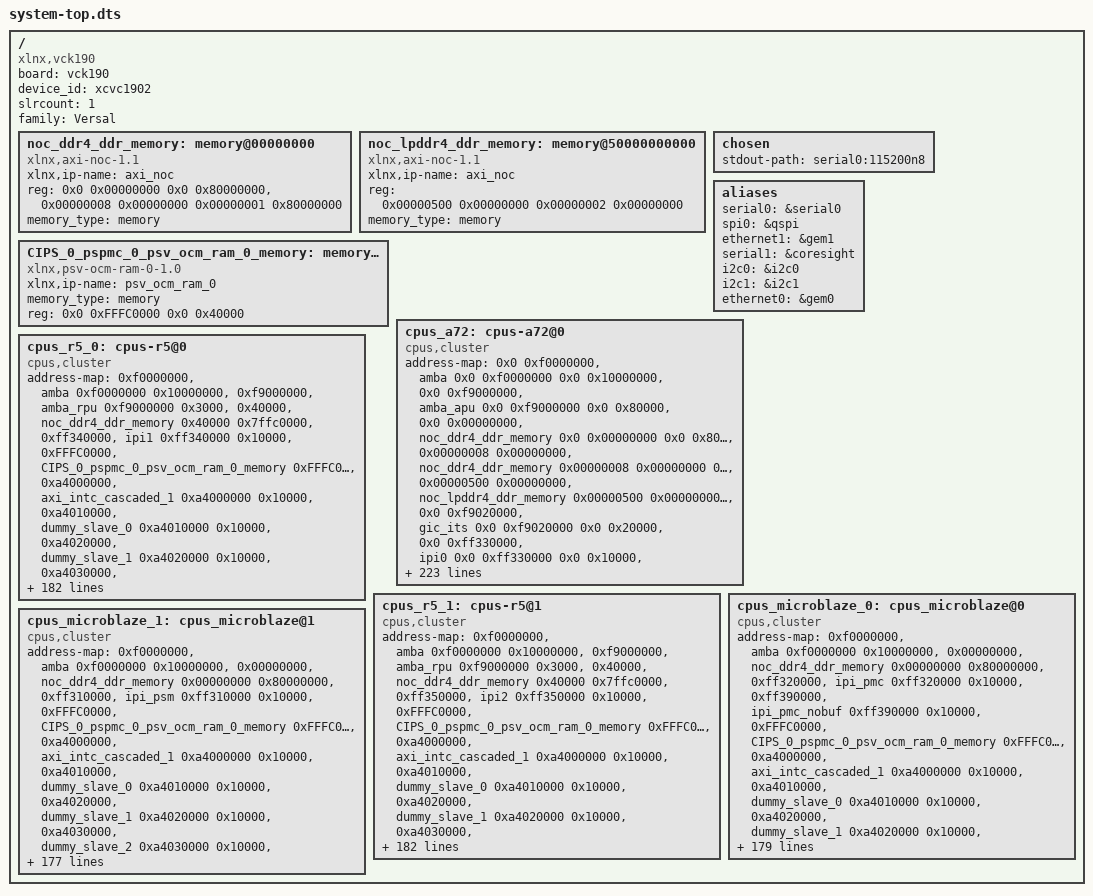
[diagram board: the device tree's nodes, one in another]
/dts-v1/;
#include "versal.dtsi"
#include "versal-clk.dtsi"
#include "pl.dtsi"
#include "pcw.dtsi"
/ {
	board = "vck190";
	compatible = "xlnx,vck190";
	device_id = "xcvc1902";
	slrcount = <1>;
	family = "Versal";
	noc_ddr4_ddr_memory: memory@00000000 {
		compatible = "xlnx,axi-noc-1.1";
		xlnx,ip-name = "axi_noc";
		device_type = "memory";
		reg = <0x0 0x00000000 0x0 0x80000000>, <0x00000008 0x00000000 0x00000001 0x80000000>;
		memory_type = "memory";
	};
	noc_lpddr4_ddr_memory: memory@50000000000 {
		compatible = "xlnx,axi-noc-1.1";
		xlnx,ip-name = "axi_noc";
		device_type = "memory";
		reg = <0x00000500 0x00000000 0x00000002 0x00000000>;
		memory_type = "memory";
	};
	CIPS_0_pspmc_0_psv_ocm_ram_0_memory: memory@FFFC0000 {
		compatible = "xlnx,psv-ocm-ram-0-1.0" , "mmio-sram";
		xlnx,ip-name = "psv_ocm_ram_0";
		device_type = "memory";
		memory_type = "memory";
		reg = <0x0 0xFFFC0000 0x0 0x40000>;
	};
	chosen {
		stdout-path = "serial0:115200n8";
	};
	aliases {
		serial0 = &serial0;
		spi0 = &qspi;
		ethernet1 = &gem1;
		serial1 = &coresight;
		i2c0 = &i2c0;
		i2c1 = &i2c1;
		ethernet0 = &gem0;
	};
	cpus_a72: cpus-a72@0 {
		compatible = "cpus,cluster";
		address-map = <0x0 0xf0000000 &amba 0x0 0xf0000000 0x0 0x10000000>, 
			      <0x0 0xf9000000 &amba_apu 0x0 0xf9000000 0x0 0x80000>, 
			      <0x0 0x00000000 &noc_ddr4_ddr_memory 0x0 0x00000000 0x0 0x80000000>, 
			      <0x00000008 0x00000000 &noc_ddr4_ddr_memory 0x00000008 0x00000000 0x00000001 0x80000000>, 
			      <0x00000500 0x00000000 &noc_lpddr4_ddr_memory 0x00000500 0x00000000 0x00000002 0x00000000>, 
			      <0x0 0xf9020000 &gic_its 0x0 0xf9020000 0x0 0x20000>, 
			      <0x0 0xff330000 &ipi0 0x0 0xff330000 0x0 0x10000>, 
			      <0x0 0xff360000 &ipi3 0x0 0xff360000 0x0 0x10000>, 
			      <0x0 0xff370000 &ipi4 0x0 0xff370000 0x0 0x10000>, 
			      <0x0 0xff380000 &ipi5 0x0 0xff380000 0x0 0x10000>, 
			      <0x0 0xff3a0000 &ipi6 0x0 0xff3a0000 0x0 0x10000>, 
			      <0x0 0xFFFC0000 &CIPS_0_pspmc_0_psv_ocm_ram_0_memory 0x0 0xFFFC0000 0x0 0x40000>, 
			      <0x0 0xa4000000 &axi_intc_cascaded_1 0x0 0xa4000000 0x0 0x10000>, 
			      <0x0 0xa4010000 &dummy_slave_0 0x0 0xa4010000 0x0 0x10000>, 
			      <0x0 0xa4020000 &dummy_slave_1 0x0 0xa4020000 0x0 0x10000>, 
			      <0x0 0xa4030000 &dummy_slave_2 0x0 0xa4030000 0x0 0x10000>, 
			      <0x0 0xa4040000 &dummy_slave_3 0x0 0xa4040000 0x0 0x10000>, 
			      <0x0 0xa5000000 &axi_intc_parent 0x0 0xa5000000 0x0 0x10000>, 
			      <0x0 0xf0310000 &CIPS_0_pspmc_0_psv_pmc_ppu1_mdm_0 0x0 0xf0310000 0x0 0x8000>, 
			      <0x0 0xf0800000 &coresight 0x0 0xf0800000 0x0 0x10000>, 
			      <0x0 0xf0980000 &CIPS_0_pspmc_0_psv_coresight_lpd_atm 0x0 0xf0980000 0x0 0x10000>, 
			      <0x0 0xf0b70000 &CIPS_0_pspmc_0_psv_coresight_fpd_stm 0x0 0xf0b70000 0x0 0x10000>, 
			      <0x0 0xf0b80000 &CIPS_0_pspmc_0_psv_coresight_fpd_atm 0x0 0xf0b80000 0x0 0x10000>, 
			      <0x0 0xf0c20000 &CIPS_0_pspmc_0_psv_coresight_apu_fun 0x0 0xf0c20000 0x0 0x10000>, 
			      <0x0 0xf0c30000 &CIPS_0_pspmc_0_psv_coresight_apu_etf 0x0 0xf0c30000 0x0 0x10000>, 
			      <0x0 0xf0c60000 &CIPS_0_pspmc_0_psv_coresight_apu_ela 0x0 0xf0c60000 0x0 0x10000>, 
			      <0x0 0xf0ca0000 &CIPS_0_pspmc_0_psv_coresight_apu_cti 0x0 0xf0ca0000 0x0 0x10000>, 
			      <0x0 0xf0d00000 &CIPS_0_pspmc_0_psv_coresight_a720_dbg 0x0 0xf0d00000 0x0 0x10000>, 
			      <0x0 0xf0d10000 &CIPS_0_pspmc_0_psv_coresight_a720_cti 0x0 0xf0d10000 0x0 0x10000>, 
			      <0x0 0xf0d20000 &CIPS_0_pspmc_0_psv_coresight_a720_pmu 0x0 0xf0d20000 0x0 0x10000>, 
			      <0x0 0xf0d30000 &CIPS_0_pspmc_0_psv_coresight_a720_etm 0x0 0xf0d30000 0x0 0x10000>, 
			      <0x0 0xf0d40000 &CIPS_0_pspmc_0_psv_coresight_a721_dbg 0x0 0xf0d40000 0x0 0x10000>, 
			      <0x0 0xf0d50000 &CIPS_0_pspmc_0_psv_coresight_a721_cti 0x0 0xf0d50000 0x0 0x10000>, 
			      <0x0 0xf0d60000 &CIPS_0_pspmc_0_psv_coresight_a721_pmu 0x0 0xf0d60000 0x0 0x10000>, 
			      <0x0 0xf0d70000 &CIPS_0_pspmc_0_psv_coresight_a721_etm 0x0 0xf0d70000 0x0 0x10000>, 
			      <0x0 0xf0f00000 &CIPS_0_pspmc_0_psv_coresight_cpm_rom 0x0 0xf0f00000 0x0 0x10000>, 
			      <0x0 0xf0f20000 &CIPS_0_pspmc_0_psv_coresight_cpm_fun 0x0 0xf0f20000 0x0 0x10000>, 
			      <0x0 0xf0f40000 &CIPS_0_pspmc_0_psv_coresight_cpm_ela2a 0x0 0xf0f40000 0x0 0x10000>, 
			      <0x0 0xf0f50000 &CIPS_0_pspmc_0_psv_coresight_cpm_ela2b 0x0 0xf0f50000 0x0 0x10000>, 
			      <0x0 0xf0f60000 &CIPS_0_pspmc_0_psv_coresight_cpm_ela2c 0x0 0xf0f60000 0x0 0x10000>, 
			      <0x0 0xf0f70000 &CIPS_0_pspmc_0_psv_coresight_cpm_ela2d 0x0 0xf0f70000 0x0 0x10000>, 
			      <0x0 0xf0f80000 &CIPS_0_pspmc_0_psv_coresight_cpm_atm 0x0 0xf0f80000 0x0 0x10000>, 
			      <0x0 0xf0fa0000 &CIPS_0_pspmc_0_psv_coresight_cpm_cti2a 0x0 0xf0fa0000 0x0 0x10000>, 
			      <0x0 0xf0fd0000 &CIPS_0_pspmc_0_psv_coresight_cpm_cti2d 0x0 0xf0fd0000 0x0 0x10000>, 
			      <0x0 0xf1020000 &gpio1 0x0 0xf1020000 0x0 0x10000>, 
			      <0x0 0xf1030000 &qspi 0x0 0xf1030000 0x0 0x10000>, 
			      <0x0 0xf1050000 &sdhci1 0x0 0xf1050000 0x0 0x10000>, 
			      <0x0 0xf1110000 &CIPS_0_pspmc_0_psv_pmc_global_0 0x0 0xf1110000 0x0 0x50000>, 
			      <0x0 0xf11c0000 &dma0 0x0 0xf11c0000 0x0 0x10000>, 
			      <0x0 0xf11d0000 &dma1 0x0 0xf11d0000 0x0 0x10000>, 
			      <0x0 0xf11e0000 &CIPS_0_pspmc_0_psv_pmc_aes 0x0 0xf11e0000 0x0 0x10000>, 
			      <0x0 0xf11f0000 &CIPS_0_pspmc_0_psv_pmc_bbram_ctrl 0x0 0xf11f0000 0x0 0x10000>, 
			      <0x0 0xf1200000 &CIPS_0_pspmc_0_psv_pmc_rsa 0x0 0xf1200000 0x0 0x10000>, 
			      <0x0 0xf1210000 &CIPS_0_pspmc_0_psv_pmc_sha 0x0 0xf1210000 0x0 0x10000>, 
			      <0x0 0xf1220000 &CIPS_0_pspmc_0_psv_pmc_slave_boot 0x0 0xf1220000 0x0 0x10000>, 
			      <0x0 0xf1230000 &CIPS_0_pspmc_0_psv_pmc_trng 0x0 0xf1230000 0x0 0x10000>, 
			      <0x0 0xf1240000 &CIPS_0_pspmc_0_psv_pmc_efuse_ctrl 0x0 0xf1240000 0x0 0x10000>, 
			      <0x0 0xf1250000 &CIPS_0_pspmc_0_psv_pmc_efuse_cache 0x0 0xf1250000 0x0 0x10000>, 
			      <0x0 0xf1260000 &CIPS_0_pspmc_0_psv_crp_0 0x0 0xf1260000 0x0 0x10000>, 
			      <0x0 0xf1270000 &sysmon0 0x0 0xf1270000 0x0 0x30000>, 
			      <0x0 0xf12a0000 &rtc 0x0 0xf12a0000 0x0 0x10000>, 
			      <0x0 0xf12b0000 &CIPS_0_pspmc_0_psv_pmc_cfu_apb_0 0x0 0xf12b0000 0x0 0x10000>, 
			      <0x0 0xf12d0000 &CIPS_0_pspmc_0_psv_pmc_cfi_cframe_0 0x0 0xf12d0000 0x0 0x1000>, 
			      <0x0 0xf12f0000 &pmc_xmpu 0x0 0xf12f0000 0x0 0x10000>, 
			      <0x0 0xf1300000 &pmc_xppu_npi 0x0 0xf1300000 0x0 0x10000>, 
			      <0x0 0xf1310000 &pmc_xppu 0x0 0xf1310000 0x0 0x10000>, 
			      <0x0 0xf2100000 &CIPS_0_pspmc_0_psv_pmc_slave_boot_stream 0x0 0xf2100000 0x0 0x10000>, 
			      <0x0 0xf6000000 &CIPS_0_pspmc_0_psv_pmc_ram_npi 0x0 0xf6000000 0x0 0x2000000>, 
			      <0x0 0xf9000000 &gic_a72 0x0 0xf9000000 0x0 0x70000>, 
			      <0x0 0 &CIPS_0_pspmc_0_psv_cpm 0x0 0 0x0 0xfd000000>, 
			      <0x0 0xfd000000 &cci 0x0 0xfd000000 0x0 0x100000>, 
			      <0x0 0xfd1a0000 &CIPS_0_pspmc_0_psv_crf_0 0x0 0xfd1a0000 0x0 0x140000>, 
			      <0x0 0xfd360000 &CIPS_0_pspmc_0_psv_fpd_afi_0 0x0 0xfd360000 0x0 0x10000>, 
			      <0x0 0xfd380000 &CIPS_0_pspmc_0_psv_fpd_afi_2 0x0 0xfd380000 0x0 0x10000>, 
			      <0x0 0xfd390000 &fpd_xmpu 0x0 0xfd390000 0x0 0x10000>, 
			      <0x0 0xfd5c0000 &CIPS_0_pspmc_0_psv_apu_0 0x0 0xfd5c0000 0x0 0x10000>, 
			      <0x0 0xfd5e0000 &CIPS_0_pspmc_0_psv_fpd_cci_0 0x0 0xfd5e0000 0x0 0x10000>, 
			      <0x0 0xfd5f0000 &CIPS_0_pspmc_0_psv_fpd_smmu_0 0x0 0xfd5f0000 0x0 0x10000>, 
			      <0x0 0xfd610000 &CIPS_0_pspmc_0_psv_fpd_slcr_0 0x0 0xfd610000 0x0 0x10000>, 
			      <0x0 0xfd690000 &CIPS_0_pspmc_0_psv_fpd_slcr_secure_0 0x0 0xfd690000 0x0 0x10000>, 
			      <0x0 0xfd700000 &CIPS_0_pspmc_0_psv_fpd_gpv_0 0x0 0xfd700000 0x0 0x100000>, 
			      <0x0 0xfd800000 &smmu 0x0 0xfd800000 0x0 0x800000>, 
			      <0x0 0xfe200000 &dwc3_0 0x0 0xfe200000 0x0 0x100000>, 
			      <0x0 0xff000000 &serial0 0x0 0xff000000 0x0 0x10000>, 
			      <0x0 0xff020000 &i2c0 0x0 0xff020000 0x0 0x10000>, 
			      <0x0 0xff030000 &i2c1 0x0 0xff030000 0x0 0x10000>, 
			      <0x0 0xff070000 &can1 0x0 0xff070000 0x0 0x10000>, 
			      <0x0 0xff080000 &CIPS_0_pspmc_0_psv_lpd_iou_slcr_0 0x0 0xff080000 0x0 0x20000>, 
			      <0x0 0xff0a0000 &CIPS_0_pspmc_0_psv_lpd_iou_secure_slcr_0 0x0 0xff0a0000 0x0 0x10000>, 
			      <0x0 0xff0c0000 &gem0 0x0 0xff0c0000 0x0 0x10000>, 
			      <0x0 0xff0d0000 &gem1 0x0 0xff0d0000 0x0 0x10000>, 
			      <0x0 0xff0e0000 &ttc0 0x0 0xff0e0000 0x0 0x10000>, 
			      <0x0 0xff0f0000 &ttc1 0x0 0xff0f0000 0x0 0x10000>, 
			      <0x0 0xff100000 &ttc2 0x0 0xff100000 0x0 0x10000>, 
			      <0x0 0xff110000 &ttc3 0x0 0xff110000 0x0 0x10000>, 
			      <0x0 0xff130000 &CIPS_0_pspmc_0_psv_scntr_0 0x0 0xff130000 0x0 0x10000>, 
			      <0x0 0xff140000 &CIPS_0_pspmc_0_psv_scntrs_0 0x0 0xff140000 0x0 0x10000>, 
			      <0x0 0xff410000 &CIPS_0_pspmc_0_psv_lpd_slcr_0 0x0 0xff410000 0x0 0x100000>, 
			      <0x0 0xff510000 &CIPS_0_pspmc_0_psv_lpd_slcr_secure_0 0x0 0xff510000 0x0 0x40000>, 
			      <0x0 0xff5e0000 &CIPS_0_pspmc_0_psv_crl_0 0x0 0xff5e0000 0x0 0x300000>, 
			      <0x0 0xff960000 &CIPS_0_pspmc_0_psv_ocm_ctrl 0x0 0xff960000 0x0 0x10000>, 
			      <0x0 0xff980000 &ocm_xmpu 0x0 0xff980000 0x0 0x10000>, 
			      <0x0 0xff990000 &lpd_xppu 0x0 0xff990000 0x0 0x10000>, 
			      <0x0 0xff9a0000 &CIPS_0_pspmc_0_psv_rpu_0 0x0 0xff9a0000 0x0 0x10000>, 
			      <0x0 0xff9b0000 &CIPS_0_pspmc_0_psv_lpd_afi_0 0x0 0xff9b0000 0x0 0x10000>, 
			      <0x0 0xff9d0000 &usb0 0x0 0xff9d0000 0x0 0x10000>, 
			      <0x0 0xffa80000 &lpd_dma_chan0 0x0 0xffa80000 0x0 0x10000>, 
			      <0x0 0xffa90000 &lpd_dma_chan1 0x0 0xffa90000 0x0 0x10000>, 
			      <0x0 0xffaa0000 &lpd_dma_chan2 0x0 0xffaa0000 0x0 0x10000>, 
			      <0x0 0xffab0000 &lpd_dma_chan3 0x0 0xffab0000 0x0 0x10000>, 
			      <0x0 0xffac0000 &lpd_dma_chan4 0x0 0xffac0000 0x0 0x10000>, 
			      <0x0 0xffad0000 &lpd_dma_chan5 0x0 0xffad0000 0x0 0x10000>, 
			      <0x0 0xffae0000 &lpd_dma_chan6 0x0 0xffae0000 0x0 0x10000>, 
			      <0x0 0xffaf0000 &lpd_dma_chan7 0x0 0xffaf0000 0x0 0x10000>, 
			      <0x0 0xffc90000 &CIPS_0_pspmc_0_psv_psm_global_reg 0x0 0xffc90000 0x0 0xf000>, 
			      <0x0 0xffe00000 &psv_r5_0_atcm_global 0x0 0xffe00000 0x0 0x40000>, 
			      <0x0 0xffe90000 &psv_r5_1_atcm_global 0x0 0xffe90000 0x0 0x10000>, 
			      <0x0 0xffeb0000 &psv_r5_1_btcm_global 0x0 0xffeb0000 0x0 0x10000>, 
			      <0x00000200 0x00000000 &ai_engine_0 0x00000200 0x00000000 0x00000001 0x00000000>;
		#ranges-address-cells = <0x2>;
		#ranges-size-cells = <0x2>;
	};
	cpus_r5_0: cpus-r5@0 {
		compatible = "cpus,cluster";
		address-map = <0xf0000000 &amba 0xf0000000 0x10000000>, 
			      <0xf9000000 &amba_rpu 0xf9000000 0x3000>, 
			      <0x40000 &noc_ddr4_ddr_memory 0x40000 0x7ffc0000>, 
			      <0xff340000 &ipi1 0xff340000 0x10000>, 
			      <0xFFFC0000 &CIPS_0_pspmc_0_psv_ocm_ram_0_memory 0xFFFC0000 0x40000>, 
			      <0xa4000000 &axi_intc_cascaded_1 0xa4000000 0x10000>, 
			      <0xa4010000 &dummy_slave_0 0xa4010000 0x10000>, 
			      <0xa4020000 &dummy_slave_1 0xa4020000 0x10000>, 
			      <0xa4030000 &dummy_slave_2 0xa4030000 0x10000>, 
			      <0xa4040000 &dummy_slave_3 0xa4040000 0x10000>, 
			      <0xa5000000 &axi_intc_parent 0xa5000000 0x10000>, 
			      <0xf0310000 &CIPS_0_pspmc_0_psv_pmc_ppu1_mdm_0 0xf0310000 0x8000>, 
			      <0xf0800000 &coresight 0xf0800000 0x10000>, 
			      <0xf0980000 &CIPS_0_pspmc_0_psv_coresight_lpd_atm 0xf0980000 0x10000>, 
			      <0xf0b70000 &CIPS_0_pspmc_0_psv_coresight_fpd_stm 0xf0b70000 0x10000>, 
			      <0xf0b80000 &CIPS_0_pspmc_0_psv_coresight_fpd_atm 0xf0b80000 0x10000>, 
			      <0xf0c20000 &CIPS_0_pspmc_0_psv_coresight_apu_fun 0xf0c20000 0x10000>, 
			      <0xf0c30000 &CIPS_0_pspmc_0_psv_coresight_apu_etf 0xf0c30000 0x10000>, 
			      <0xf0c60000 &CIPS_0_pspmc_0_psv_coresight_apu_ela 0xf0c60000 0x10000>, 
			      <0xf0ca0000 &CIPS_0_pspmc_0_psv_coresight_apu_cti 0xf0ca0000 0x10000>, 
			      <0xf0d00000 &CIPS_0_pspmc_0_psv_coresight_a720_dbg 0xf0d00000 0x10000>, 
			      <0xf0d10000 &CIPS_0_pspmc_0_psv_coresight_a720_cti 0xf0d10000 0x10000>, 
			      <0xf0d20000 &CIPS_0_pspmc_0_psv_coresight_a720_pmu 0xf0d20000 0x10000>, 
			      <0xf0d30000 &CIPS_0_pspmc_0_psv_coresight_a720_etm 0xf0d30000 0x10000>, 
			      <0xf0d40000 &CIPS_0_pspmc_0_psv_coresight_a721_dbg 0xf0d40000 0x10000>, 
			      <0xf0d50000 &CIPS_0_pspmc_0_psv_coresight_a721_cti 0xf0d50000 0x10000>, 
			      <0xf0d60000 &CIPS_0_pspmc_0_psv_coresight_a721_pmu 0xf0d60000 0x10000>, 
			      <0xf0d70000 &CIPS_0_pspmc_0_psv_coresight_a721_etm 0xf0d70000 0x10000>, 
			      <0xf0f00000 &CIPS_0_pspmc_0_psv_coresight_cpm_rom 0xf0f00000 0x10000>, 
			      <0xf0f20000 &CIPS_0_pspmc_0_psv_coresight_cpm_fun 0xf0f20000 0x10000>, 
			      <0xf0f40000 &CIPS_0_pspmc_0_psv_coresight_cpm_ela2a 0xf0f40000 0x10000>, 
			      <0xf0f50000 &CIPS_0_pspmc_0_psv_coresight_cpm_ela2b 0xf0f50000 0x10000>, 
			      <0xf0f60000 &CIPS_0_pspmc_0_psv_coresight_cpm_ela2c 0xf0f60000 0x10000>, 
			      <0xf0f70000 &CIPS_0_pspmc_0_psv_coresight_cpm_ela2d 0xf0f70000 0x10000>, 
			      <0xf0f80000 &CIPS_0_pspmc_0_psv_coresight_cpm_atm 0xf0f80000 0x10000>, 
			      <0xf0fa0000 &CIPS_0_pspmc_0_psv_coresight_cpm_cti2a 0xf0fa0000 0x10000>, 
			      <0xf0fd0000 &CIPS_0_pspmc_0_psv_coresight_cpm_cti2d 0xf0fd0000 0x10000>, 
			      <0xf1020000 &gpio1 0xf1020000 0x10000>, 
			      <0xf1030000 &qspi 0xf1030000 0x10000>, 
			      <0xf1050000 &sdhci1 0xf1050000 0x10000>, 
			      <0xf1110000 &CIPS_0_pspmc_0_psv_pmc_global_0 0xf1110000 0x50000>, 
			      <0xf11c0000 &dma0 0xf11c0000 0x10000>, 
			      <0xf11d0000 &dma1 0xf11d0000 0x10000>, 
			      <0xf11e0000 &CIPS_0_pspmc_0_psv_pmc_aes 0xf11e0000 0x10000>, 
			      <0xf11f0000 &CIPS_0_pspmc_0_psv_pmc_bbram_ctrl 0xf11f0000 0x10000>, 
			      <0xf1200000 &CIPS_0_pspmc_0_psv_pmc_rsa 0xf1200000 0x10000>, 
			      <0xf1210000 &CIPS_0_pspmc_0_psv_pmc_sha 0xf1210000 0x10000>, 
			      <0xf1220000 &CIPS_0_pspmc_0_psv_pmc_slave_boot 0xf1220000 0x10000>, 
			      <0xf1230000 &CIPS_0_pspmc_0_psv_pmc_trng 0xf1230000 0x10000>, 
			      <0xf1240000 &CIPS_0_pspmc_0_psv_pmc_efuse_ctrl 0xf1240000 0x10000>, 
			      <0xf1250000 &CIPS_0_pspmc_0_psv_pmc_efuse_cache 0xf1250000 0x10000>, 
			      <0xf1260000 &CIPS_0_pspmc_0_psv_crp_0 0xf1260000 0x10000>, 
			      <0xf1270000 &sysmon0 0xf1270000 0x30000>, 
			      <0xf12a0000 &rtc 0xf12a0000 0x10000>, 
			      <0xf12b0000 &CIPS_0_pspmc_0_psv_pmc_cfu_apb_0 0xf12b0000 0x10000>, 
			      <0xf12d0000 &CIPS_0_pspmc_0_psv_pmc_cfi_cframe_0 0xf12d0000 0x1000>, 
			      <0xf12f0000 &pmc_xmpu 0xf12f0000 0x10000>, 
			      <0xf1300000 &pmc_xppu_npi 0xf1300000 0x10000>, 
			      <0xf1310000 &pmc_xppu 0xf1310000 0x10000>, 
			      <0xf2100000 &CIPS_0_pspmc_0_psv_pmc_slave_boot_stream 0xf2100000 0x10000>, 
			      <0xf6000000 &CIPS_0_pspmc_0_psv_pmc_ram_npi 0xf6000000 0x2000000>, 
			      <0xfd000000 &cci 0xfd000000 0x100000>, 
			      <0xfd1a0000 &CIPS_0_pspmc_0_psv_crf_0 0xfd1a0000 0x140000>, 
			      <0xfd360000 &CIPS_0_pspmc_0_psv_fpd_afi_0 0xfd360000 0x10000>, 
			      <0xfd380000 &CIPS_0_pspmc_0_psv_fpd_afi_2 0xfd380000 0x10000>, 
			      <0xfd390000 &fpd_xmpu 0xfd390000 0x10000>, 
			      <0xfd5c0000 &CIPS_0_pspmc_0_psv_apu_0 0xfd5c0000 0x10000>, 
			      <0xfd5e0000 &CIPS_0_pspmc_0_psv_fpd_cci_0 0xfd5e0000 0x10000>, 
			      <0xfd5f0000 &CIPS_0_pspmc_0_psv_fpd_smmu_0 0xfd5f0000 0x10000>, 
			      <0xfd610000 &CIPS_0_pspmc_0_psv_fpd_slcr_0 0xfd610000 0x10000>, 
			      <0xfd690000 &CIPS_0_pspmc_0_psv_fpd_slcr_secure_0 0xfd690000 0x10000>, 
			      <0xfd700000 &CIPS_0_pspmc_0_psv_fpd_gpv_0 0xfd700000 0x100000>, 
			      <0xfd800000 &smmu 0xfd800000 0x800000>, 
			      <0xfe200000 &dwc3_0 0xfe200000 0x100000>, 
			      <0xff000000 &serial0 0xff000000 0x10000>, 
			      <0xff020000 &i2c0 0xff020000 0x10000>, 
			      <0xff030000 &i2c1 0xff030000 0x10000>, 
			      <0xff070000 &can1 0xff070000 0x10000>, 
			      <0xff080000 &CIPS_0_pspmc_0_psv_lpd_iou_slcr_0 0xff080000 0x20000>, 
			      <0xff0a0000 &CIPS_0_pspmc_0_psv_lpd_iou_secure_slcr_0 0xff0a0000 0x10000>, 
			      <0xff0c0000 &gem0 0xff0c0000 0x10000>, 
			      <0xff0d0000 &gem1 0xff0d0000 0x10000>, 
			      <0xff0e0000 &ttc0 0xff0e0000 0x10000>, 
			      <0xff0f0000 &ttc1 0xff0f0000 0x10000>, 
			      <0xff100000 &ttc2 0xff100000 0x10000>, 
			      <0xff110000 &ttc3 0xff110000 0x10000>, 
			      <0xff130000 &CIPS_0_pspmc_0_psv_scntr_0 0xff130000 0x10000>, 
			      <0xff140000 &CIPS_0_pspmc_0_psv_scntrs_0 0xff140000 0x10000>, 
			      <0xff410000 &CIPS_0_pspmc_0_psv_lpd_slcr_0 0xff410000 0x100000>, 
			      <0xff510000 &CIPS_0_pspmc_0_psv_lpd_slcr_secure_0 0xff510000 0x40000>, 
			      <0xff5e0000 &CIPS_0_pspmc_0_psv_crl_0 0xff5e0000 0x300000>, 
			      <0xff960000 &CIPS_0_pspmc_0_psv_ocm_ctrl 0xff960000 0x10000>, 
			      <0xff980000 &ocm_xmpu 0xff980000 0x10000>, 
			      <0xff990000 &lpd_xppu 0xff990000 0x10000>, 
			      <0xff9a0000 &CIPS_0_pspmc_0_psv_rpu_0 0xff9a0000 0x10000>, 
			      <0xff9b0000 &CIPS_0_pspmc_0_psv_lpd_afi_0 0xff9b0000 0x10000>, 
			      <0xff9d0000 &usb0 0xff9d0000 0x10000>, 
			      <0xffa80000 &lpd_dma_chan0 0xffa80000 0x10000>, 
			      <0xffa90000 &lpd_dma_chan1 0xffa90000 0x10000>, 
			      <0xffaa0000 &lpd_dma_chan2 0xffaa0000 0x10000>, 
			      <0xffab0000 &lpd_dma_chan3 0xffab0000 0x10000>, 
			      <0xffac0000 &lpd_dma_chan4 0xffac0000 0x10000>, 
			      <0xffad0000 &lpd_dma_chan5 0xffad0000 0x10000>, 
			      <0xffae0000 &lpd_dma_chan6 0xffae0000 0x10000>, 
			      <0xffaf0000 &lpd_dma_chan7 0xffaf0000 0x10000>, 
			      <0xffc90000 &CIPS_0_pspmc_0_psv_psm_global_reg 0xffc90000 0xf000>, 
			      <0x0000 &CIPS_0_pspmc_0_psv_r5_0_atcm 0x0000 0x10000>, 
			      <0x00000 &CIPS_0_pspmc_0_psv_r5_tcm_ram_0 0x00000 0x40000>, 
			      <0x20000 &CIPS_0_pspmc_0_psv_r5_0_btcm 0x20000 0x10000>, 
			      <0xf9000000 &gic_r5 0xf9000000 0x3000>, 
			      <0xffe40000 &CIPS_0_pspmc_0_psv_r5_0_instruction_cache 0xffe40000 0x10000>, 
			      <0xffe50000 &CIPS_0_pspmc_0_psv_r5_0_data_cache 0xffe50000 0x10000>, 
			      <0xffec0000 &CIPS_0_pspmc_0_psv_r5_1_instruction_cache 0xffec0000 0x10000>, 
			      <0xffed0000 &CIPS_0_pspmc_0_psv_r5_1_data_cache 0xffed0000 0x10000>;
		#ranges-address-cells = <0x1>;
		#ranges-size-cells = <0x1>;
	};
	cpus_r5_1: cpus-r5@1 {
		compatible = "cpus,cluster";
		address-map = <0xf0000000 &amba 0xf0000000 0x10000000>, 
			      <0xf9000000 &amba_rpu 0xf9000000 0x3000>, 
			      <0x40000 &noc_ddr4_ddr_memory 0x40000 0x7ffc0000>, 
			      <0xff350000 &ipi2 0xff350000 0x10000>, 
			      <0xFFFC0000 &CIPS_0_pspmc_0_psv_ocm_ram_0_memory 0xFFFC0000 0x40000>, 
			      <0xa4000000 &axi_intc_cascaded_1 0xa4000000 0x10000>, 
			      <0xa4010000 &dummy_slave_0 0xa4010000 0x10000>, 
			      <0xa4020000 &dummy_slave_1 0xa4020000 0x10000>, 
			      <0xa4030000 &dummy_slave_2 0xa4030000 0x10000>, 
			      <0xa4040000 &dummy_slave_3 0xa4040000 0x10000>, 
			      <0xa5000000 &axi_intc_parent 0xa5000000 0x10000>, 
			      <0xf0310000 &CIPS_0_pspmc_0_psv_pmc_ppu1_mdm_0 0xf0310000 0x8000>, 
			      <0xf0800000 &coresight 0xf0800000 0x10000>, 
			      <0xf0980000 &CIPS_0_pspmc_0_psv_coresight_lpd_atm 0xf0980000 0x10000>, 
			      <0xf0b70000 &CIPS_0_pspmc_0_psv_coresight_fpd_stm 0xf0b70000 0x10000>, 
			      <0xf0b80000 &CIPS_0_pspmc_0_psv_coresight_fpd_atm 0xf0b80000 0x10000>, 
			      <0xf0c20000 &CIPS_0_pspmc_0_psv_coresight_apu_fun 0xf0c20000 0x10000>, 
			      <0xf0c30000 &CIPS_0_pspmc_0_psv_coresight_apu_etf 0xf0c30000 0x10000>, 
			      <0xf0c60000 &CIPS_0_pspmc_0_psv_coresight_apu_ela 0xf0c60000 0x10000>, 
			      <0xf0ca0000 &CIPS_0_pspmc_0_psv_coresight_apu_cti 0xf0ca0000 0x10000>, 
			      <0xf0d00000 &CIPS_0_pspmc_0_psv_coresight_a720_dbg 0xf0d00000 0x10000>, 
			      <0xf0d10000 &CIPS_0_pspmc_0_psv_coresight_a720_cti 0xf0d10000 0x10000>, 
			      <0xf0d20000 &CIPS_0_pspmc_0_psv_coresight_a720_pmu 0xf0d20000 0x10000>, 
			      <0xf0d30000 &CIPS_0_pspmc_0_psv_coresight_a720_etm 0xf0d30000 0x10000>, 
			      <0xf0d40000 &CIPS_0_pspmc_0_psv_coresight_a721_dbg 0xf0d40000 0x10000>, 
			      <0xf0d50000 &CIPS_0_pspmc_0_psv_coresight_a721_cti 0xf0d50000 0x10000>, 
			      <0xf0d60000 &CIPS_0_pspmc_0_psv_coresight_a721_pmu 0xf0d60000 0x10000>, 
			      <0xf0d70000 &CIPS_0_pspmc_0_psv_coresight_a721_etm 0xf0d70000 0x10000>, 
			      <0xf0f00000 &CIPS_0_pspmc_0_psv_coresight_cpm_rom 0xf0f00000 0x10000>, 
			      <0xf0f20000 &CIPS_0_pspmc_0_psv_coresight_cpm_fun 0xf0f20000 0x10000>, 
			      <0xf0f40000 &CIPS_0_pspmc_0_psv_coresight_cpm_ela2a 0xf0f40000 0x10000>, 
			      <0xf0f50000 &CIPS_0_pspmc_0_psv_coresight_cpm_ela2b 0xf0f50000 0x10000>, 
			      <0xf0f60000 &CIPS_0_pspmc_0_psv_coresight_cpm_ela2c 0xf0f60000 0x10000>, 
			      <0xf0f70000 &CIPS_0_pspmc_0_psv_coresight_cpm_ela2d 0xf0f70000 0x10000>, 
			      <0xf0f80000 &CIPS_0_pspmc_0_psv_coresight_cpm_atm 0xf0f80000 0x10000>, 
			      <0xf0fa0000 &CIPS_0_pspmc_0_psv_coresight_cpm_cti2a 0xf0fa0000 0x10000>, 
			      <0xf0fd0000 &CIPS_0_pspmc_0_psv_coresight_cpm_cti2d 0xf0fd0000 0x10000>, 
			      <0xf1020000 &gpio1 0xf1020000 0x10000>, 
			      <0xf1030000 &qspi 0xf1030000 0x10000>, 
			      <0xf1050000 &sdhci1 0xf1050000 0x10000>, 
			      <0xf1110000 &CIPS_0_pspmc_0_psv_pmc_global_0 0xf1110000 0x50000>, 
			      <0xf11c0000 &dma0 0xf11c0000 0x10000>, 
			      <0xf11d0000 &dma1 0xf11d0000 0x10000>, 
			      <0xf11e0000 &CIPS_0_pspmc_0_psv_pmc_aes 0xf11e0000 0x10000>, 
			      <0xf11f0000 &CIPS_0_pspmc_0_psv_pmc_bbram_ctrl 0xf11f0000 0x10000>, 
			      <0xf1200000 &CIPS_0_pspmc_0_psv_pmc_rsa 0xf1200000 0x10000>, 
			      <0xf1210000 &CIPS_0_pspmc_0_psv_pmc_sha 0xf1210000 0x10000>, 
			      <0xf1220000 &CIPS_0_pspmc_0_psv_pmc_slave_boot 0xf1220000 0x10000>, 
			      <0xf1230000 &CIPS_0_pspmc_0_psv_pmc_trng 0xf1230000 0x10000>, 
			      <0xf1240000 &CIPS_0_pspmc_0_psv_pmc_efuse_ctrl 0xf1240000 0x10000>, 
			      <0xf1250000 &CIPS_0_pspmc_0_psv_pmc_efuse_cache 0xf1250000 0x10000>, 
			      <0xf1260000 &CIPS_0_pspmc_0_psv_crp_0 0xf1260000 0x10000>, 
			      <0xf1270000 &sysmon0 0xf1270000 0x30000>, 
			      <0xf12a0000 &rtc 0xf12a0000 0x10000>, 
			      <0xf12b0000 &CIPS_0_pspmc_0_psv_pmc_cfu_apb_0 0xf12b0000 0x10000>, 
			      <0xf12d0000 &CIPS_0_pspmc_0_psv_pmc_cfi_cframe_0 0xf12d0000 0x1000>, 
			      <0xf12f0000 &pmc_xmpu 0xf12f0000 0x10000>, 
			      <0xf1300000 &pmc_xppu_npi 0xf1300000 0x10000>, 
			      <0xf1310000 &pmc_xppu 0xf1310000 0x10000>, 
			      <0xf2100000 &CIPS_0_pspmc_0_psv_pmc_slave_boot_stream 0xf2100000 0x10000>, 
			      <0xf6000000 &CIPS_0_pspmc_0_psv_pmc_ram_npi 0xf6000000 0x2000000>, 
			      <0xfd000000 &cci 0xfd000000 0x100000>, 
			      <0xfd1a0000 &CIPS_0_pspmc_0_psv_crf_0 0xfd1a0000 0x140000>, 
			      <0xfd360000 &CIPS_0_pspmc_0_psv_fpd_afi_0 0xfd360000 0x10000>, 
			      <0xfd380000 &CIPS_0_pspmc_0_psv_fpd_afi_2 0xfd380000 0x10000>, 
			      <0xfd390000 &fpd_xmpu 0xfd390000 0x10000>, 
			      <0xfd5c0000 &CIPS_0_pspmc_0_psv_apu_0 0xfd5c0000 0x10000>, 
			      <0xfd5e0000 &CIPS_0_pspmc_0_psv_fpd_cci_0 0xfd5e0000 0x10000>, 
			      <0xfd5f0000 &CIPS_0_pspmc_0_psv_fpd_smmu_0 0xfd5f0000 0x10000>, 
			      <0xfd610000 &CIPS_0_pspmc_0_psv_fpd_slcr_0 0xfd610000 0x10000>, 
			      <0xfd690000 &CIPS_0_pspmc_0_psv_fpd_slcr_secure_0 0xfd690000 0x10000>, 
			      <0xfd700000 &CIPS_0_pspmc_0_psv_fpd_gpv_0 0xfd700000 0x100000>, 
			      <0xfd800000 &smmu 0xfd800000 0x800000>, 
			      <0xfe200000 &dwc3_0 0xfe200000 0x100000>, 
			      <0xff000000 &serial0 0xff000000 0x10000>, 
			      <0xff020000 &i2c0 0xff020000 0x10000>, 
			      <0xff030000 &i2c1 0xff030000 0x10000>, 
			      <0xff070000 &can1 0xff070000 0x10000>, 
			      <0xff080000 &CIPS_0_pspmc_0_psv_lpd_iou_slcr_0 0xff080000 0x20000>, 
			      <0xff0a0000 &CIPS_0_pspmc_0_psv_lpd_iou_secure_slcr_0 0xff0a0000 0x10000>, 
			      <0xff0c0000 &gem0 0xff0c0000 0x10000>, 
			      <0xff0d0000 &gem1 0xff0d0000 0x10000>, 
			      <0xff0e0000 &ttc0 0xff0e0000 0x10000>, 
			      <0xff0f0000 &ttc1 0xff0f0000 0x10000>, 
			      <0xff100000 &ttc2 0xff100000 0x10000>, 
			      <0xff110000 &ttc3 0xff110000 0x10000>, 
			      <0xff130000 &CIPS_0_pspmc_0_psv_scntr_0 0xff130000 0x10000>, 
			      <0xff140000 &CIPS_0_pspmc_0_psv_scntrs_0 0xff140000 0x10000>, 
			      <0xff410000 &CIPS_0_pspmc_0_psv_lpd_slcr_0 0xff410000 0x100000>, 
			      <0xff510000 &CIPS_0_pspmc_0_psv_lpd_slcr_secure_0 0xff510000 0x40000>, 
			      <0xff5e0000 &CIPS_0_pspmc_0_psv_crl_0 0xff5e0000 0x300000>, 
			      <0xff960000 &CIPS_0_pspmc_0_psv_ocm_ctrl 0xff960000 0x10000>, 
			      <0xff980000 &ocm_xmpu 0xff980000 0x10000>, 
			      <0xff990000 &lpd_xppu 0xff990000 0x10000>, 
			      <0xff9a0000 &CIPS_0_pspmc_0_psv_rpu_0 0xff9a0000 0x10000>, 
			      <0xff9b0000 &CIPS_0_pspmc_0_psv_lpd_afi_0 0xff9b0000 0x10000>, 
			      <0xff9d0000 &usb0 0xff9d0000 0x10000>, 
			      <0xffa80000 &lpd_dma_chan0 0xffa80000 0x10000>, 
			      <0xffa90000 &lpd_dma_chan1 0xffa90000 0x10000>, 
			      <0xffaa0000 &lpd_dma_chan2 0xffaa0000 0x10000>, 
			      <0xffab0000 &lpd_dma_chan3 0xffab0000 0x10000>, 
			      <0xffac0000 &lpd_dma_chan4 0xffac0000 0x10000>, 
			      <0xffad0000 &lpd_dma_chan5 0xffad0000 0x10000>, 
			      <0xffae0000 &lpd_dma_chan6 0xffae0000 0x10000>, 
			      <0xffaf0000 &lpd_dma_chan7 0xffaf0000 0x10000>, 
			      <0xffc90000 &CIPS_0_pspmc_0_psv_psm_global_reg 0xffc90000 0xf000>, 
			      <0x00000 &CIPS_0_pspmc_0_psv_r5_tcm_ram_0 0x00000 0x40000>, 
			      <0xf9000000 &gic_r5 0xf9000000 0x3000>, 
			      <0xffe40000 &CIPS_0_pspmc_0_psv_r5_0_instruction_cache 0xffe40000 0x10000>, 
			      <0xffe50000 &CIPS_0_pspmc_0_psv_r5_0_data_cache 0xffe50000 0x10000>, 
			      <0xffec0000 &CIPS_0_pspmc_0_psv_r5_1_instruction_cache 0xffec0000 0x10000>, 
			      <0xffed0000 &CIPS_0_pspmc_0_psv_r5_1_data_cache 0xffed0000 0x10000>, 
			      <0x0000 &CIPS_0_pspmc_0_psv_r5_1_atcm 0x0000 0x10000>, 
			      <0x20000 &CIPS_0_pspmc_0_psv_r5_1_btcm 0x20000 0x10000>;
		#ranges-address-cells = <0x1>;
		#ranges-size-cells = <0x1>;
	};
	cpus_microblaze_0: cpus_microblaze@0 {
		compatible = "cpus,cluster";
		address-map = <0xf0000000 &amba 0xf0000000 0x10000000>, 
			      <0x00000000 &noc_ddr4_ddr_memory 0x00000000 0x80000000>, 
			      <0xff320000 &ipi_pmc 0xff320000 0x10000>, 
			      <0xff390000 &ipi_pmc_nobuf 0xff390000 0x10000>, 
			      <0xFFFC0000 &CIPS_0_pspmc_0_psv_ocm_ram_0_memory 0xFFFC0000 0x40000>, 
			      <0xa4000000 &axi_intc_cascaded_1 0xa4000000 0x10000>, 
			      <0xa4010000 &dummy_slave_0 0xa4010000 0x10000>, 
			      <0xa4020000 &dummy_slave_1 0xa4020000 0x10000>, 
			      <0xa4030000 &dummy_slave_2 0xa4030000 0x10000>, 
			      <0xa4040000 &dummy_slave_3 0xa4040000 0x10000>, 
			      <0xa5000000 &axi_intc_parent 0xa5000000 0x10000>, 
			      <0xf0310000 &CIPS_0_pspmc_0_psv_pmc_ppu1_mdm_0 0xf0310000 0x8000>, 
			      <0xf0980000 &CIPS_0_pspmc_0_psv_coresight_lpd_atm 0xf0980000 0x10000>, 
			      <0xf0b70000 &CIPS_0_pspmc_0_psv_coresight_fpd_stm 0xf0b70000 0x10000>, 
			      <0xf0b80000 &CIPS_0_pspmc_0_psv_coresight_fpd_atm 0xf0b80000 0x10000>, 
			      <0xf0c20000 &CIPS_0_pspmc_0_psv_coresight_apu_fun 0xf0c20000 0x10000>, 
			      <0xf0c30000 &CIPS_0_pspmc_0_psv_coresight_apu_etf 0xf0c30000 0x10000>, 
			      <0xf0c60000 &CIPS_0_pspmc_0_psv_coresight_apu_ela 0xf0c60000 0x10000>, 
			      <0xf0ca0000 &CIPS_0_pspmc_0_psv_coresight_apu_cti 0xf0ca0000 0x10000>, 
			      <0xf0d00000 &CIPS_0_pspmc_0_psv_coresight_a720_dbg 0xf0d00000 0x10000>, 
			      <0xf0d10000 &CIPS_0_pspmc_0_psv_coresight_a720_cti 0xf0d10000 0x10000>, 
			      <0xf0d20000 &CIPS_0_pspmc_0_psv_coresight_a720_pmu 0xf0d20000 0x10000>, 
			      <0xf0d30000 &CIPS_0_pspmc_0_psv_coresight_a720_etm 0xf0d30000 0x10000>, 
			      <0xf0d40000 &CIPS_0_pspmc_0_psv_coresight_a721_dbg 0xf0d40000 0x10000>, 
			      <0xf0d50000 &CIPS_0_pspmc_0_psv_coresight_a721_cti 0xf0d50000 0x10000>, 
			      <0xf0d60000 &CIPS_0_pspmc_0_psv_coresight_a721_pmu 0xf0d60000 0x10000>, 
			      <0xf0d70000 &CIPS_0_pspmc_0_psv_coresight_a721_etm 0xf0d70000 0x10000>, 
			      <0xf0f00000 &CIPS_0_pspmc_0_psv_coresight_cpm_rom 0xf0f00000 0x10000>, 
			      <0xf0f20000 &CIPS_0_pspmc_0_psv_coresight_cpm_fun 0xf0f20000 0x10000>, 
			      <0xf0f40000 &CIPS_0_pspmc_0_psv_coresight_cpm_ela2a 0xf0f40000 0x10000>, 
			      <0xf0f50000 &CIPS_0_pspmc_0_psv_coresight_cpm_ela2b 0xf0f50000 0x10000>, 
			      <0xf0f60000 &CIPS_0_pspmc_0_psv_coresight_cpm_ela2c 0xf0f60000 0x10000>, 
			      <0xf0f70000 &CIPS_0_pspmc_0_psv_coresight_cpm_ela2d 0xf0f70000 0x10000>, 
			      <0xf0f80000 &CIPS_0_pspmc_0_psv_coresight_cpm_atm 0xf0f80000 0x10000>, 
			      <0xf0fa0000 &CIPS_0_pspmc_0_psv_coresight_cpm_cti2a 0xf0fa0000 0x10000>, 
			      <0xf0fd0000 &CIPS_0_pspmc_0_psv_coresight_cpm_cti2d 0xf0fd0000 0x10000>, 
			      <0xf1020000 &gpio1 0xf1020000 0x10000>, 
			      <0xf1030000 &qspi 0xf1030000 0x10000>, 
			      <0xf1050000 &sdhci1 0xf1050000 0x10000>, 
			      <0xf1110000 &CIPS_0_pspmc_0_psv_pmc_global_0 0xf1110000 0x50000>, 
			      <0xf11c0000 &dma0 0xf11c0000 0x10000>, 
			      <0xf11d0000 &dma1 0xf11d0000 0x10000>, 
			      <0xf11e0000 &CIPS_0_pspmc_0_psv_pmc_aes 0xf11e0000 0x10000>, 
			      <0xf11f0000 &CIPS_0_pspmc_0_psv_pmc_bbram_ctrl 0xf11f0000 0x10000>, 
			      <0xf1200000 &CIPS_0_pspmc_0_psv_pmc_rsa 0xf1200000 0x10000>, 
			      <0xf1210000 &CIPS_0_pspmc_0_psv_pmc_sha 0xf1210000 0x10000>, 
			      <0xf1220000 &CIPS_0_pspmc_0_psv_pmc_slave_boot 0xf1220000 0x10000>, 
			      <0xf1230000 &CIPS_0_pspmc_0_psv_pmc_trng 0xf1230000 0x10000>, 
			      <0xf1240000 &CIPS_0_pspmc_0_psv_pmc_efuse_ctrl 0xf1240000 0x10000>, 
			      <0xf1250000 &CIPS_0_pspmc_0_psv_pmc_efuse_cache 0xf1250000 0x10000>, 
			      <0xf1260000 &CIPS_0_pspmc_0_psv_crp_0 0xf1260000 0x10000>, 
			      <0xf1270000 &sysmon0 0xf1270000 0x30000>, 
			      <0xf12a0000 &rtc 0xf12a0000 0x10000>, 
			      <0xf12b0000 &CIPS_0_pspmc_0_psv_pmc_cfu_apb_0 0xf12b0000 0x10000>, 
			      <0xf12d0000 &CIPS_0_pspmc_0_psv_pmc_cfi_cframe_0 0xf12d0000 0x1000>, 
			      <0xf12f0000 &pmc_xmpu 0xf12f0000 0x10000>, 
			      <0xf1300000 &pmc_xppu_npi 0xf1300000 0x10000>, 
			      <0xf1310000 &pmc_xppu 0xf1310000 0x10000>, 
			      <0xf2100000 &CIPS_0_pspmc_0_psv_pmc_slave_boot_stream 0xf2100000 0x10000>, 
			      <0xf6000000 &CIPS_0_pspmc_0_psv_pmc_ram_npi 0xf6000000 0x2000000>, 
			      <0 &CIPS_0_pspmc_0_psv_cpm 0 0xfd000000>, 
			      <0xfd000000 &cci 0xfd000000 0x100000>, 
			      <0xfd1a0000 &CIPS_0_pspmc_0_psv_crf_0 0xfd1a0000 0x140000>, 
			      <0xfd360000 &CIPS_0_pspmc_0_psv_fpd_afi_0 0xfd360000 0x10000>, 
			      <0xfd380000 &CIPS_0_pspmc_0_psv_fpd_afi_2 0xfd380000 0x10000>, 
			      <0xfd390000 &fpd_xmpu 0xfd390000 0x10000>, 
			      <0xfd5e0000 &CIPS_0_pspmc_0_psv_fpd_cci_0 0xfd5e0000 0x10000>, 
			      <0xfd5f0000 &CIPS_0_pspmc_0_psv_fpd_smmu_0 0xfd5f0000 0x10000>, 
			      <0xfd610000 &CIPS_0_pspmc_0_psv_fpd_slcr_0 0xfd610000 0x10000>, 
			      <0xfd690000 &CIPS_0_pspmc_0_psv_fpd_slcr_secure_0 0xfd690000 0x10000>, 
			      <0xfd700000 &CIPS_0_pspmc_0_psv_fpd_gpv_0 0xfd700000 0x100000>, 
			      <0xfd800000 &smmu 0xfd800000 0x800000>, 
			      <0xfe200000 &dwc3_0 0xfe200000 0x100000>, 
			      <0xff000000 &serial0 0xff000000 0x10000>, 
			      <0xff020000 &i2c0 0xff020000 0x10000>, 
			      <0xff030000 &i2c1 0xff030000 0x10000>, 
			      <0xff070000 &can1 0xff070000 0x10000>, 
			      <0xff080000 &CIPS_0_pspmc_0_psv_lpd_iou_slcr_0 0xff080000 0x20000>, 
			      <0xff0a0000 &CIPS_0_pspmc_0_psv_lpd_iou_secure_slcr_0 0xff0a0000 0x10000>, 
			      <0xff0c0000 &gem0 0xff0c0000 0x10000>, 
			      <0xff0d0000 &gem1 0xff0d0000 0x10000>, 
			      <0xff0e0000 &ttc0 0xff0e0000 0x10000>, 
			      <0xff0f0000 &ttc1 0xff0f0000 0x10000>, 
			      <0xff100000 &ttc2 0xff100000 0x10000>, 
			      <0xff110000 &ttc3 0xff110000 0x10000>, 
			      <0xff130000 &CIPS_0_pspmc_0_psv_scntr_0 0xff130000 0x10000>, 
			      <0xff140000 &CIPS_0_pspmc_0_psv_scntrs_0 0xff140000 0x10000>, 
			      <0xff410000 &CIPS_0_pspmc_0_psv_lpd_slcr_0 0xff410000 0x100000>, 
			      <0xff510000 &CIPS_0_pspmc_0_psv_lpd_slcr_secure_0 0xff510000 0x40000>, 
			      <0xff5e0000 &CIPS_0_pspmc_0_psv_crl_0 0xff5e0000 0x300000>, 
			      <0xff960000 &CIPS_0_pspmc_0_psv_ocm_ctrl 0xff960000 0x10000>, 
			      <0xff980000 &ocm_xmpu 0xff980000 0x10000>, 
			      <0xff990000 &lpd_xppu 0xff990000 0x10000>, 
			      <0xff9b0000 &CIPS_0_pspmc_0_psv_lpd_afi_0 0xff9b0000 0x10000>, 
			      <0xff9d0000 &usb0 0xff9d0000 0x10000>, 
			      <0xffa80000 &lpd_dma_chan0 0xffa80000 0x10000>, 
			      <0xffa90000 &lpd_dma_chan1 0xffa90000 0x10000>, 
			      <0xffaa0000 &lpd_dma_chan2 0xffaa0000 0x10000>, 
			      <0xffab0000 &lpd_dma_chan3 0xffab0000 0x10000>, 
			      <0xffac0000 &lpd_dma_chan4 0xffac0000 0x10000>, 
			      <0xffad0000 &lpd_dma_chan5 0xffad0000 0x10000>, 
			      <0xffae0000 &lpd_dma_chan6 0xffae0000 0x10000>, 
			      <0xffaf0000 &lpd_dma_chan7 0xffaf0000 0x10000>, 
			      <0xffc90000 &CIPS_0_pspmc_0_psv_psm_global_reg 0xffc90000 0xf000>, 
			      <0xffe00000 &psv_r5_0_atcm_global 0xffe00000 0x40000>, 
			      <0xffe90000 &psv_r5_1_atcm_global 0xffe90000 0x10000>, 
			      <0xffeb0000 &psv_r5_1_btcm_global 0xffeb0000 0x10000>, 
			      <0xf0083000 &CIPS_0_pspmc_0_psv_pmc_tmr_inject_0 0xf0083000 0x1000>, 
			      <0xf0200000 &CIPS_0_pspmc_0_psv_pmc_ram_instr_cntlr 0xf0200000 0x40000>, 
			      <0xf0240000 &CIPS_0_pspmc_0_psv_pmc_ram_data_cntlr 0xf0240000 0x20000>, 
			      <0xf0280000 &iomodule0 0xf0280000 0x1000>, 
			      <0xf0283000 &CIPS_0_pspmc_0_psv_pmc_tmr_manager_0 0xf0283000 0x1000>;
		#ranges-address-cells = <0x1>;
		#ranges-size-cells = <0x1>;
	};
	cpus_microblaze_1: cpus_microblaze@1 {
		compatible = "cpus,cluster";
		address-map = <0xf0000000 &amba 0xf0000000 0x10000000>, 
			      <0x00000000 &noc_ddr4_ddr_memory 0x00000000 0x80000000>, 
			      <0xff310000 &ipi_psm 0xff310000 0x10000>, 
			      <0xFFFC0000 &CIPS_0_pspmc_0_psv_ocm_ram_0_memory 0xFFFC0000 0x40000>, 
			      <0xa4000000 &axi_intc_cascaded_1 0xa4000000 0x10000>, 
			      <0xa4010000 &dummy_slave_0 0xa4010000 0x10000>, 
			      <0xa4020000 &dummy_slave_1 0xa4020000 0x10000>, 
			      <0xa4030000 &dummy_slave_2 0xa4030000 0x10000>, 
			      <0xa4040000 &dummy_slave_3 0xa4040000 0x10000>, 
			      <0xa5000000 &axi_intc_parent 0xa5000000 0x10000>, 
			      <0xf0310000 &CIPS_0_pspmc_0_psv_pmc_ppu1_mdm_0 0xf0310000 0x8000>, 
			      <0xf0980000 &CIPS_0_pspmc_0_psv_coresight_lpd_atm 0xf0980000 0x10000>, 
			      <0xf0b70000 &CIPS_0_pspmc_0_psv_coresight_fpd_stm 0xf0b70000 0x10000>, 
			      <0xf0b80000 &CIPS_0_pspmc_0_psv_coresight_fpd_atm 0xf0b80000 0x10000>, 
			      <0xf0c20000 &CIPS_0_pspmc_0_psv_coresight_apu_fun 0xf0c20000 0x10000>, 
			      <0xf0c30000 &CIPS_0_pspmc_0_psv_coresight_apu_etf 0xf0c30000 0x10000>, 
			      <0xf0c60000 &CIPS_0_pspmc_0_psv_coresight_apu_ela 0xf0c60000 0x10000>, 
			      <0xf0ca0000 &CIPS_0_pspmc_0_psv_coresight_apu_cti 0xf0ca0000 0x10000>, 
			      <0xf0d00000 &CIPS_0_pspmc_0_psv_coresight_a720_dbg 0xf0d00000 0x10000>, 
			      <0xf0d10000 &CIPS_0_pspmc_0_psv_coresight_a720_cti 0xf0d10000 0x10000>, 
			      <0xf0d20000 &CIPS_0_pspmc_0_psv_coresight_a720_pmu 0xf0d20000 0x10000>, 
			      <0xf0d30000 &CIPS_0_pspmc_0_psv_coresight_a720_etm 0xf0d30000 0x10000>, 
			      <0xf0d40000 &CIPS_0_pspmc_0_psv_coresight_a721_dbg 0xf0d40000 0x10000>, 
			      <0xf0d50000 &CIPS_0_pspmc_0_psv_coresight_a721_cti 0xf0d50000 0x10000>, 
			      <0xf0d60000 &CIPS_0_pspmc_0_psv_coresight_a721_pmu 0xf0d60000 0x10000>, 
			      <0xf0d70000 &CIPS_0_pspmc_0_psv_coresight_a721_etm 0xf0d70000 0x10000>, 
			      <0xf0f00000 &CIPS_0_pspmc_0_psv_coresight_cpm_rom 0xf0f00000 0x10000>, 
			      <0xf0f20000 &CIPS_0_pspmc_0_psv_coresight_cpm_fun 0xf0f20000 0x10000>, 
			      <0xf0f40000 &CIPS_0_pspmc_0_psv_coresight_cpm_ela2a 0xf0f40000 0x10000>, 
			      <0xf0f50000 &CIPS_0_pspmc_0_psv_coresight_cpm_ela2b 0xf0f50000 0x10000>, 
			      <0xf0f60000 &CIPS_0_pspmc_0_psv_coresight_cpm_ela2c 0xf0f60000 0x10000>, 
			      <0xf0f70000 &CIPS_0_pspmc_0_psv_coresight_cpm_ela2d 0xf0f70000 0x10000>, 
			      <0xf0f80000 &CIPS_0_pspmc_0_psv_coresight_cpm_atm 0xf0f80000 0x10000>, 
			      <0xf0fa0000 &CIPS_0_pspmc_0_psv_coresight_cpm_cti2a 0xf0fa0000 0x10000>, 
			      <0xf0fd0000 &CIPS_0_pspmc_0_psv_coresight_cpm_cti2d 0xf0fd0000 0x10000>, 
			      <0xf1020000 &gpio1 0xf1020000 0x10000>, 
			      <0xf1030000 &qspi 0xf1030000 0x10000>, 
			      <0xf1050000 &sdhci1 0xf1050000 0x10000>, 
			      <0xf1110000 &CIPS_0_pspmc_0_psv_pmc_global_0 0xf1110000 0x50000>, 
			      <0xf11c0000 &dma0 0xf11c0000 0x10000>, 
			      <0xf11d0000 &dma1 0xf11d0000 0x10000>, 
			      <0xf11e0000 &CIPS_0_pspmc_0_psv_pmc_aes 0xf11e0000 0x10000>, 
			      <0xf11f0000 &CIPS_0_pspmc_0_psv_pmc_bbram_ctrl 0xf11f0000 0x10000>, 
			      <0xf1200000 &CIPS_0_pspmc_0_psv_pmc_rsa 0xf1200000 0x10000>, 
			      <0xf1210000 &CIPS_0_pspmc_0_psv_pmc_sha 0xf1210000 0x10000>, 
			      <0xf1220000 &CIPS_0_pspmc_0_psv_pmc_slave_boot 0xf1220000 0x10000>, 
			      <0xf1230000 &CIPS_0_pspmc_0_psv_pmc_trng 0xf1230000 0x10000>, 
			      <0xf1240000 &CIPS_0_pspmc_0_psv_pmc_efuse_ctrl 0xf1240000 0x10000>, 
			      <0xf1250000 &CIPS_0_pspmc_0_psv_pmc_efuse_cache 0xf1250000 0x10000>, 
			      <0xf1260000 &CIPS_0_pspmc_0_psv_crp_0 0xf1260000 0x10000>, 
			      <0xf1270000 &sysmon0 0xf1270000 0x30000>, 
			      <0xf12a0000 &rtc 0xf12a0000 0x10000>, 
			      <0xf12b0000 &CIPS_0_pspmc_0_psv_pmc_cfu_apb_0 0xf12b0000 0x10000>, 
			      <0xf12d0000 &CIPS_0_pspmc_0_psv_pmc_cfi_cframe_0 0xf12d0000 0x1000>, 
			      <0xf12f0000 &pmc_xmpu 0xf12f0000 0x10000>, 
			      <0xf1300000 &pmc_xppu_npi 0xf1300000 0x10000>, 
			      <0xf1310000 &pmc_xppu 0xf1310000 0x10000>, 
			      <0xf2100000 &CIPS_0_pspmc_0_psv_pmc_slave_boot_stream 0xf2100000 0x10000>, 
			      <0xf6000000 &CIPS_0_pspmc_0_psv_pmc_ram_npi 0xf6000000 0x2000000>, 
			      <0xfd000000 &cci 0xfd000000 0x100000>, 
			      <0xfd1a0000 &CIPS_0_pspmc_0_psv_crf_0 0xfd1a0000 0x140000>, 
			      <0xfd360000 &CIPS_0_pspmc_0_psv_fpd_afi_0 0xfd360000 0x10000>, 
			      <0xfd380000 &CIPS_0_pspmc_0_psv_fpd_afi_2 0xfd380000 0x10000>, 
			      <0xfd390000 &fpd_xmpu 0xfd390000 0x10000>, 
			      <0xfd5e0000 &CIPS_0_pspmc_0_psv_fpd_cci_0 0xfd5e0000 0x10000>, 
			      <0xfd5f0000 &CIPS_0_pspmc_0_psv_fpd_smmu_0 0xfd5f0000 0x10000>, 
			      <0xfd610000 &CIPS_0_pspmc_0_psv_fpd_slcr_0 0xfd610000 0x10000>, 
			      <0xfd690000 &CIPS_0_pspmc_0_psv_fpd_slcr_secure_0 0xfd690000 0x10000>, 
			      <0xfd700000 &CIPS_0_pspmc_0_psv_fpd_gpv_0 0xfd700000 0x100000>, 
			      <0xfd800000 &smmu 0xfd800000 0x800000>, 
			      <0xfe200000 &dwc3_0 0xfe200000 0x100000>, 
			      <0xff000000 &serial0 0xff000000 0x10000>, 
			      <0xff020000 &i2c0 0xff020000 0x10000>, 
			      <0xff030000 &i2c1 0xff030000 0x10000>, 
			      <0xff070000 &can1 0xff070000 0x10000>, 
			      <0xff080000 &CIPS_0_pspmc_0_psv_lpd_iou_slcr_0 0xff080000 0x20000>, 
			      <0xff0a0000 &CIPS_0_pspmc_0_psv_lpd_iou_secure_slcr_0 0xff0a0000 0x10000>, 
			      <0xff0c0000 &gem0 0xff0c0000 0x10000>, 
			      <0xff0d0000 &gem1 0xff0d0000 0x10000>, 
			      <0xff0e0000 &ttc0 0xff0e0000 0x10000>, 
			      <0xff0f0000 &ttc1 0xff0f0000 0x10000>, 
			      <0xff100000 &ttc2 0xff100000 0x10000>, 
			      <0xff110000 &ttc3 0xff110000 0x10000>, 
			      <0xff130000 &CIPS_0_pspmc_0_psv_scntr_0 0xff130000 0x10000>, 
			      <0xff140000 &CIPS_0_pspmc_0_psv_scntrs_0 0xff140000 0x10000>, 
			      <0xff410000 &CIPS_0_pspmc_0_psv_lpd_slcr_0 0xff410000 0x100000>, 
			      <0xff510000 &CIPS_0_pspmc_0_psv_lpd_slcr_secure_0 0xff510000 0x40000>, 
			      <0xff5e0000 &CIPS_0_pspmc_0_psv_crl_0 0xff5e0000 0x300000>, 
			      <0xff960000 &CIPS_0_pspmc_0_psv_ocm_ctrl 0xff960000 0x10000>, 
			      <0xff980000 &ocm_xmpu 0xff980000 0x10000>, 
			      <0xff990000 &lpd_xppu 0xff990000 0x10000>, 
			      <0xff9b0000 &CIPS_0_pspmc_0_psv_lpd_afi_0 0xff9b0000 0x10000>, 
			      <0xff9d0000 &usb0 0xff9d0000 0x10000>, 
			      <0xffa80000 &lpd_dma_chan0 0xffa80000 0x10000>, 
			      <0xffa90000 &lpd_dma_chan1 0xffa90000 0x10000>, 
			      <0xffaa0000 &lpd_dma_chan2 0xffaa0000 0x10000>, 
			      <0xffab0000 &lpd_dma_chan3 0xffab0000 0x10000>, 
			      <0xffac0000 &lpd_dma_chan4 0xffac0000 0x10000>, 
			      <0xffad0000 &lpd_dma_chan5 0xffad0000 0x10000>, 
			      <0xffae0000 &lpd_dma_chan6 0xffae0000 0x10000>, 
			      <0xffaf0000 &lpd_dma_chan7 0xffaf0000 0x10000>, 
			      <0xffc90000 &CIPS_0_pspmc_0_psv_psm_global_reg 0xffc90000 0xf000>, 
			      <0xffe00000 &psv_r5_0_atcm_global 0xffe00000 0x40000>, 
			      <0xffe90000 &psv_r5_1_atcm_global 0xffe90000 0x10000>, 
			      <0xffeb0000 &psv_r5_1_btcm_global 0xffeb0000 0x10000>, 
			      <0xffc00000 &CIPS_0_pspmc_0_psv_psm_ram_instr_cntlr 0xffc00000 0x20000>, 
			      <0xffc20000 &CIPS_0_pspmc_0_psv_psm_ram_data_cntlr 0xffc20000 0x20000>, 
			      <0xffc80000 &CIPS_0_pspmc_0_psv_psm_iomodule_0 0xffc80000 0x8000>, 
			      <0xffcc0000 &CIPS_0_pspmc_0_psv_psm_tmr_manager_0 0xffcc0000 0x10000>, 
			      <0xffcd0000 &CIPS_0_pspmc_0_psv_psm_tmr_inject_0 0xffcd0000 0x10000>;
		#ranges-address-cells = <0x1>;
		#ranges-size-cells = <0x1>;
	};
};
